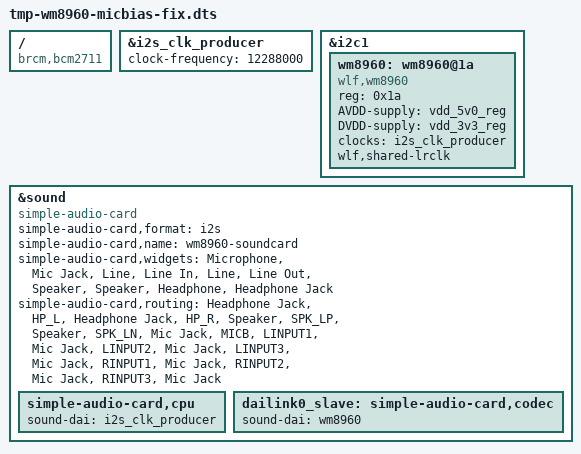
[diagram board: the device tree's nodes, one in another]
/dts-v1/;
/plugin/;

/ {
    compatible = "brcm,bcm2711";

    fragment@0 {
        target = <&i2s_clk_producer>;
        frag0: __overlay__ {
            #clock-cells = <0>;
            clock-frequency = <12288000>;
            status = "okay";
        };
    };

    fragment@1 {
        target = <&i2c1>;
        __overlay__ {
            #address-cells = <1>;
            #size-cells = <0>;
            status = "okay";

            wm8960: wm8960@1a {
                compatible = "wlf,wm8960";
                reg = <0x1a>;
                #sound-dai-cells = <0>;
                AVDD-supply = <&vdd_5v0_reg>;
                DVDD-supply = <&vdd_3v3_reg>;
                clocks = <&i2s_clk_producer>;
                clock-names = "mclk";
                wlf,shared-lrclk;
            };
        };
    };

    fragment@2 {
        target = <&sound>;
        slave_overlay: __overlay__ {
            compatible = "simple-audio-card";
            simple-audio-card,format = "i2s";
            simple-audio-card,name = "wm8960-soundcard";
            status = "okay";
            simple-audio-card,widgets =
                "Microphone", "Mic Jack",
                "Line", "Line In",
                "Line", "Line Out",
                "Speaker", "Speaker",
                "Headphone", "Headphone Jack";
            simple-audio-card,routing =
                "Headphone Jack", "HP_L",
                "Headphone Jack", "HP_R",
                "Speaker", "SPK_LP",
                "Speaker", "SPK_LN",
                "Mic Jack", "MICB",
                "LINPUT1", "Mic Jack",
                "LINPUT2", "Mic Jack",
                "LINPUT3", "Mic Jack",
                "RINPUT1", "Mic Jack",
                "RINPUT2", "Mic Jack",
                "RINPUT3", "Mic Jack";

            simple-audio-card,cpu {
                sound-dai = <&i2s_clk_producer>;
            };

            dailink0_slave: simple-audio-card,codec {
                sound-dai = <&wm8960>;
            };
        };
    };

    __overrides__ {
        alsaname = <&slave_overlay>,"simple-audio-card,name";
        compatible = <&wm8960>,"compatible";
    };
};
